# CCS__Compact_System_Clock_1 register map
Vendor: Texas Instruments
Peripheral module from a debugger description file (folder msp430).
Registers are 16-bit, read-write, reset 0x0 unless marked. A register's access mark holds for its fields unless they carry their own. Offsets are as the file gives them; lines under a group give offsets from that group; [hi:lo] are bit positions; {n}, {i} and the like mark numbered series; 'fields as' and 'values as' point back to an identical list; <NAME> marks a mode.

## CCS_Compact_System_Clock
0x160 CCSCTL0 access not given reset not defined — CCS Control Register 0
0x162 CCSCTL1 — CCS Control Register 1
  [0] DIVCLK — Clock division for CLKIN / X-OSC
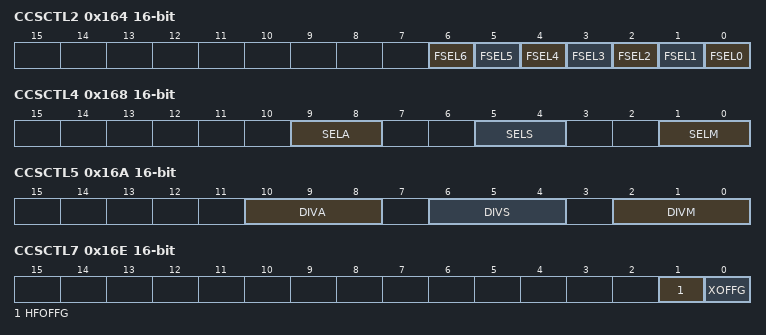
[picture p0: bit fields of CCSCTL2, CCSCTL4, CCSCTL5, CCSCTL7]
0x164 CCSCTL2 — CCS Control Register 2
  [n] FSEL{n} (n=0..6) — Frequency trimming of the HF-OSC Bit: {n}
0x168 CCSCTL4 — CCS Control Register 4
  [9:8] SELA — ACLK Source Select Bit: 0
    {v}=ACLK Source Select {v} (v=0..3)
  [5:4] SELS — SMCLK Source Select Bit: 0
    {v}=SMCLK Source Select {v} (v=0..3)
  [1:0] SELM — MCLK Source Select Bit: 0
    {v}=MCLK Source Select {v} (v=0..3)
0x16A CCSCTL5 — CCS Control Register 5
  [10:8] DIVA — ACLK Divider Bit: 0
    {v}=ACLK Source Divider {v} (v=0..5)
  [6:4] DIVS — SMCLK Divider Bit: 0
    {v}=SMCLK Source Divider {v} (v=0..5)
  [2:0] DIVM — MCLK Divider Bit: 0
    {v}=MCLK Source Divider {v} (v=0..5)
0x16C CCSCTL6 — CCS Control Register 6
  [0] XTOFF — Disable XT oscillator
0x16E CCSCTL7 — CCS Control Register 7
  [1] HFOFFG — High Frequency Oscillator Fault Flag
  [0] XOFFG — X-tal Oscillator Fault Flag
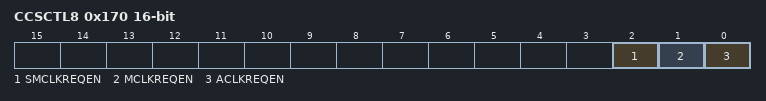
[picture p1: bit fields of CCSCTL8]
0x170 CCSCTL8 — CCS Control Register 8
  [2] SMCLKREQEN — SMCLK Clock Request Enable
  [1] MCLKREQEN — MCLK Clock Request Enable
  [0] ACLKREQEN — ACLK Clock Request Enable
